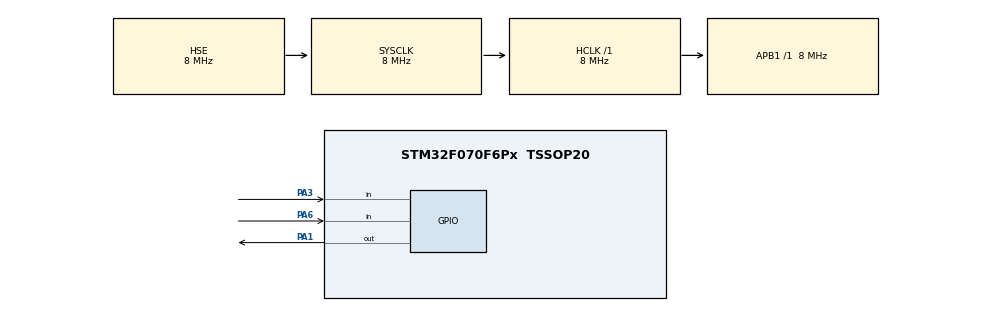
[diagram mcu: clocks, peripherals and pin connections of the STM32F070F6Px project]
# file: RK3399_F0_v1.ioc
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Mcu.Family=STM32F0
Mcu.Name=STM32F070F6Px
Mcu.Package=TSSOP20
NVIC.TIM1_BRK_UP_TRG_COM_IRQn=true\:0\:0\:false\:false\:true\:true
NVIC.TIM3_IRQn=true\:0\:0\:false\:false\:true\:true
PA1.GPIO_PuPd=GPIO_NOPULL
PA1.PinState=GPIO_PIN_SET
PA1.Signal=GPIO_Output
PA13.Mode=Serial_Wire
PA13.Signal=SYS_SWDIO
PA14.Mode=Serial_Wire
PA14.Signal=SYS_SWCLK
PA3.Signal=GPIO_Input
PA6.Signal=GPIO_Input
PF0-OSC_IN.Mode=HSE-External-Oscillator
PF0-OSC_IN.Signal=RCC_OSC_IN
PF1-OSC_OUT.Mode=HSE-External-Oscillator
PF1-OSC_OUT.Signal=RCC_OSC_OUT
ProjectManager.HeapSize=0x200
ProjectManager.StackSize=0x400
ProjectManager.TargetToolchain=MDK-ARM V5
RCC.AHBFreq_Value=8000000
RCC.APB1Freq_Value=8000000
RCC.APB1TimFreq_Value=8000000
RCC.HCLKFreq_Value=8000000
RCC.PLLSourceVirtual=RCC_PLLSOURCE_HSE
RCC.SYSCLKFreq_VALUE=8000000
RCC.SYSCLKSource=RCC_SYSCLKSOURCE_HSE
TIM1.Period=60000-1
TIM1.Prescaler=40000-1
TIM3.Period=65000-1
TIM3.Prescaler=8000-1
VP_TIM1_VS_ClockSourceINT.Mode=Internal
VP_TIM3_VS_ClockSourceINT.Mode=Internal
board=custom

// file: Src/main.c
/**
  ******************************************************************************
  * @file           : main.c
  * @brief          : Main program body
  ******************************************************************************
  ** This notice applies to any and all portions of this file
  * that are not between comment pairs USER CODE BEGIN and
  * USER CODE END. Other portions of this file, whether
  * inserted by the user or by software development tools
  * are owned by their respective copyright owners.
  *
  * COPYRIGHT(c) 2019 STMicroelectronics
  *
  * Redistribution and use in source and binary forms, with or without modification,
  * are permitted provided that the following conditions are met:
  *   1. Redistributions of source code must retain the above copyright notice,
  *      this list of conditions and the following disclaimer.
  *   2. Redistributions in binary form must reproduce the above copyright notice,
  *      this list of conditions and the following disclaimer in the documentation
  *      and/or other materials provided with the distribution.
  *   3. Neither the name of STMicroelectronics nor the names of its contributors
  *      may be used to endorse or promote products derived from this software
  *      without specific prior written permission.
  *
  * THIS SOFTWARE IS PROVIDED BY THE COPYRIGHT HOLDERS AND CONTRIBUTORS "AS IS"
  * AND ANY EXPRESS OR IMPLIED WARRANTIES, INCLUDING, BUT NOT LIMITED TO, THE
  * IMPLIED WARRANTIES OF MERCHANTABILITY AND FITNESS FOR A PARTICULAR PURPOSE ARE
  * DISCLAIMED. IN NO EVENT SHALL THE COPYRIGHT HOLDER OR CONTRIBUTORS BE LIABLE
  * FOR ANY DIRECT, INDIRECT, INCIDENTAL, SPECIAL, EXEMPLARY, OR CONSEQUENTIAL
  * DAMAGES (INCLUDING, BUT NOT LIMITED TO, PROCUREMENT OF SUBSTITUTE GOODS OR
  * SERVICES; LOSS OF USE, DATA, OR PROFITS; OR BUSINESS INTERRUPTION) HOWEVER
  * CAUSED AND ON ANY THEORY OF LIABILITY, WHETHER IN CONTRACT, STRICT LIABILITY,
  * OR TORT (INCLUDING NEGLIGENCE OR OTHERWISE) ARISING IN ANY WAY OUT OF THE USE
  * OF THIS SOFTWARE, EVEN IF ADVISED OF THE POSSIBILITY OF SUCH DAMAGE.
  *
  ******************************************************************************
  */
#include "main.h"
#include "stm32f0xx_hal.h"
#include "tim.h"
#include "gpio.h"

/* USER CODE BEGIN PV */
/* Private variables ---------------------------------------------------------*/
volatile uint8_t WatchDog_Flag = 0;

/* USER CODE END PV */

void SystemClock_Config(void);

/* USER CODE BEGIN PFP */
/* Private function prototypes -----------------------------------------------*/

/* USER CODE END PFP */

/* USER CODE BEGIN 0 */
#define TIME_OUT	2200
#define MAX 2000
#define MIN 200

/* USER CODE END 0 */

int main(void)
{

  /* MCU Configuration----------------------------------------------------------*/

  /* Reset of all peripherals, Initializes the Flash interface and the Systick. */
  HAL_Init();

  /* Configure the system clock */
  SystemClock_Config();

  /* Initialize all configured peripherals */
  MX_GPIO_Init();
  MX_TIM1_Init();
  MX_TIM3_Init();
  /* USER CODE BEGIN 2 */
	GPIO_PinState old_pin_state = GPIO_PIN_RESET;
	GPIO_PinState pin_state = GPIO_PIN_RESET;
	__HAL_TIM_CLEAR_FLAG(&htim1,TIM_FLAG_UPDATE);
	HAL_TIM_Base_Start_IT(&htim1);
	uint8_t sleep = 0;
	uint32_t i = 0;
	volatile uint32_t old_time = 0;
	volatile uint32_t now_time = 0;

  /* USER CODE END 2 */

  /* Infinite loop */
  while (1)
  {

  /* USER CODE BEGIN 3 */
		if(WatchDog_Flag >= 4)
		{
			HAL_TIM_Base_Stop_IT(&htim1);
			HAL_GPIO_WritePin(GPIOA,GPIO_PIN_1,GPIO_PIN_RESET);
			HAL_Delay(60000);
			HAL_GPIO_WritePin(GPIOA,GPIO_PIN_1,GPIO_PIN_SET);
			htim1.Instance->CNT = 0;
			__HAL_TIM_CLEAR_FLAG(&htim1,TIM_FLAG_UPDATE);
			HAL_TIM_Base_Start_IT(&htim1);
			WatchDog_Flag = 0;
		}
		pin_state = HAL_GPIO_ReadPin(GPIOA,GPIO_PIN_6);
		if(pin_state != old_pin_state)
		{
			//reset timer and watchdog_flag
			WatchDog_Flag = 0;
			HAL_TIM_Base_Stop_IT(&htim1);
			htim1.Instance->CNT = 0;
			__HAL_TIM_CLEAR_FLAG(&htim1,TIM_FLAG_UPDATE);
			HAL_TIM_Base_Start_IT(&htim1);
			old_pin_state = pin_state;
		}

		if(HAL_GPIO_ReadPin(GPIOA,GPIO_PIN_2) == GPIO_PIN_SET)
		{
			htim3.Instance->CNT = 0;
			HAL_TIM_Base_Start(&htim3);
			sleep = 1;

			old_time = htim3.Instance->CNT;
			while((HAL_GPIO_ReadPin(GPIOA,GPIO_PIN_2) == GPIO_PIN_SET) && sleep)
			{
				now_time = htim3.Instance->CNT;
				if((now_time - old_time) > TIME_OUT)
				{
//					sleep = 0;
					break;
				}
			}
			if(((now_time - old_time) < MAX) && ((now_time - old_time) > MIN))
				sleep = 1;
			else
				sleep = 0;

			old_time = htim3.Instance->CNT;
			while((HAL_GPIO_ReadPin(GPIOA,GPIO_PIN_2) == GPIO_PIN_RESET) && sleep)
			{
				now_time = htim3.Instance->CNT;
				if((now_time - old_time) > TIME_OUT)
				{
//					sleep = 0;
					break;
				}
			}
			if(((now_time - old_time) < MAX) && ((now_time - old_time) > MIN))
				sleep = 1;
			else
				sleep = 0;

			old_time = htim3.Instance->CNT;
			while((HAL_GPIO_ReadPin(GPIOA,GPIO_PIN_2) == GPIO_PIN_SET) && sleep)
			{
				now_time = htim3.Instance->CNT;
				if((now_time - old_time) > TIME_OUT)
				{
//					sleep = 0;
					break;
				}
			}
			if(((now_time - old_time) < MAX) && ((now_time - old_time) > MIN))
				sleep = 1;
			else
				sleep = 0;

			old_time = htim3.Instance->CNT;
			while((HAL_GPIO_ReadPin(GPIOA,GPIO_PIN_2) == GPIO_PIN_RESET) && sleep)
			{
				now_time = htim3.Instance->CNT;
				if((now_time - old_time) > TIME_OUT)
				{
//					sleep = 0;
					break;
				}
			}
			if(((now_time - old_time) < MAX) && ((now_time - old_time) > MIN))
				sleep = 1;
			else
				sleep = 0;

			old_time = htim3.Instance->CNT;
			while((HAL_GPIO_ReadPin(GPIOA,GPIO_PIN_2) == GPIO_PIN_SET) && sleep)
			{
				now_time = htim3.Instance->CNT;
				if((now_time - old_time) > TIME_OUT)
				{
//					sleep = 0;
					break;
				}
			}
			if(((now_time - old_time) < MAX) && ((now_time - old_time) > MIN))
				sleep = 1;
			else
				sleep = 0;

			if(sleep == 1)
			{
				//stop timer1
				HAL_TIM_Base_Stop_IT(&htim1);
				HAL_GPIO_WritePin(GPIOA,GPIO_PIN_1,GPIO_PIN_RESET);
				for(i = 0; i < 1200; i++)
					HAL_Delay(1000);
				HAL_GPIO_WritePin(GPIOA,GPIO_PIN_1,GPIO_PIN_SET);
				//restart timer 1
				__HAL_TIM_CLEAR_FLAG(&htim1,TIM_FLAG_UPDATE);
				HAL_TIM_Base_Start_IT(&htim1);
				WatchDog_Flag = 0;
			}
			HAL_TIM_Base_Stop(&htim3);
		}

  }
  /* USER CODE END 3 */

}

void SystemClock_Config(void)
{

  RCC_OscInitTypeDef RCC_OscInitStruct;
  RCC_ClkInitTypeDef RCC_ClkInitStruct;

    /**Initializes the CPU, AHB and APB busses clocks
    */
  RCC_OscInitStruct.OscillatorType = RCC_OSCILLATORTYPE_HSE;
  RCC_OscInitStruct.HSEState = RCC_HSE_ON;
  RCC_OscInitStruct.PLL.PLLState = RCC_PLL_NONE;
  if (HAL_RCC_OscConfig(&RCC_OscInitStruct) != HAL_OK)
  {
    _Error_Handler(__FILE__, __LINE__);
  }

    /**Initializes the CPU, AHB and APB busses clocks
    */
  RCC_ClkInitStruct.ClockType = RCC_CLOCKTYPE_HCLK|RCC_CLOCKTYPE_SYSCLK
                              |RCC_CLOCKTYPE_PCLK1;
  RCC_ClkInitStruct.SYSCLKSource = RCC_SYSCLKSOURCE_HSE;
  RCC_ClkInitStruct.AHBCLKDivider = RCC_SYSCLK_DIV1;
  RCC_ClkInitStruct.APB1CLKDivider = RCC_HCLK_DIV1;

  if (HAL_RCC_ClockConfig(&RCC_ClkInitStruct, FLASH_LATENCY_0) != HAL_OK)
  {
    _Error_Handler(__FILE__, __LINE__);
  }

    /**Configure the Systick interrupt time
    */
  HAL_SYSTICK_Config(HAL_RCC_GetHCLKFreq()/1000);

    /**Configure the Systick
    */
  HAL_SYSTICK_CLKSourceConfig(SYSTICK_CLKSOURCE_HCLK);

  /* SysTick_IRQn interrupt configuration */
  HAL_NVIC_SetPriority(SysTick_IRQn, 0, 0);
}

/* USER CODE BEGIN 4 */
void HAL_TIM_PeriodElapsedCallback(TIM_HandleTypeDef *htim)
{
	if(htim->Instance == htim1.Instance)
		WatchDog_Flag++;
}

/* USER CODE END 4 */

void _Error_Handler(char *file, int line)
{
  while(1)
  {
  }
}

/************************ (C) COPYRIGHT STMicroelectronics *****END OF FILE****/
